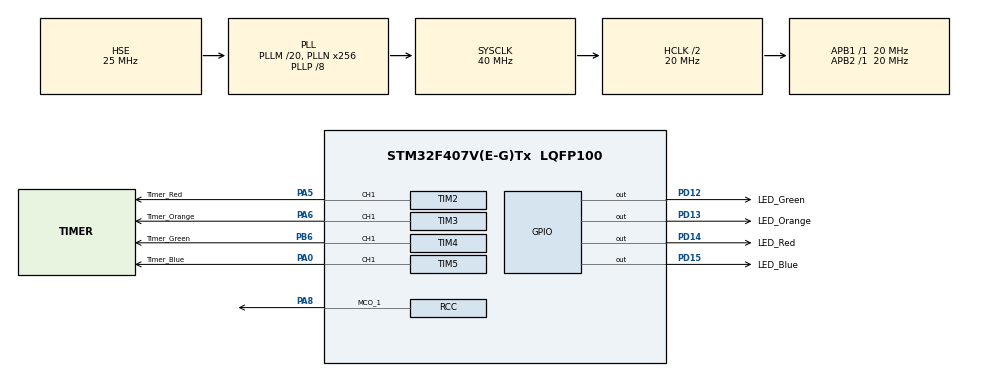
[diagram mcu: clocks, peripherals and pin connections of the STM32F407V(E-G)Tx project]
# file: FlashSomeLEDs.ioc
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Mcu.Family=STM32F4
Mcu.Name=STM32F407V(E-G)Tx
Mcu.Package=LQFP100
NVIC.PriorityGroup=NVIC_PRIORITYGROUP_4
NVIC.TIM2_IRQn=true\:0\:0\:false\:false\:true\:true\:true
NVIC.TIM3_IRQn=true\:0\:0\:false\:false\:true\:true\:true
NVIC.TIM4_IRQn=true\:0\:0\:false\:false\:true\:true\:true
NVIC.TIM5_IRQn=true\:0\:0\:false\:false\:true\:true\:true
PA0-WKUP.GPIO_Label=Timer_Blue
PA0-WKUP.Signal=S_TIM5_CH1
PA5.GPIO_Label=Timer_Red
PA5.Signal=S_TIM2_CH1_ETR
PA6.GPIO_Label=Timer_Orange
PA6.Signal=S_TIM3_CH1
PA8.Mode=Clock-out-1
PA8.Signal=RCC_MCO_1
PB6.GPIO_Label=Timer_Green
PB6.Signal=S_TIM4_CH1
PD12.GPIO_Label=LED_Green
PD12.Signal=GPIO_Output
PD13.GPIO_Label=LED_Orange
PD13.Signal=GPIO_Output
PD14.GPIO_Label=LED_Red
PD14.Signal=GPIO_Output
PD15.GPIO_Label=LED_Blue
PD15.Signal=GPIO_Output
PH0-OSC_IN.Mode=HSE-External-Oscillator
PH0-OSC_IN.Signal=RCC_OSC_IN
PH1-OSC_OUT.Mode=HSE-External-Oscillator
PH1-OSC_OUT.Signal=RCC_OSC_OUT
ProjectManager.HeapSize=0x200
ProjectManager.StackSize=0x400
ProjectManager.TargetToolchain=SW4STM32
RCC.48MHZClocksFreq_Value=80000000
RCC.AHBCLKDivider=RCC_SYSCLK_DIV2
RCC.AHBFreq_Value=20000000
RCC.APB1Freq_Value=20000000
RCC.APB1TimFreq_Value=20000000
RCC.APB2Freq_Value=20000000
RCC.APB2TimFreq_Value=20000000
RCC.CortexFreq_Value=20000000
RCC.HCLKFreq_Value=20000000
RCC.HSE_VALUE=25000000
RCC.HSI_VALUE=16000000
RCC.LSE_VALUE=32768
RCC.PLLM=20
RCC.PLLN=256
RCC.PLLP=RCC_PLLP_DIV8
RCC.PLLSourceVirtual=RCC_PLLSOURCE_HSE
RCC.SYSCLKFreq_VALUE=40000000
RCC.SYSCLKSource=RCC_SYSCLKSOURCE_PLLCLK
RCC.VCOOutputFreq_Value=320000000
SH.S_TIM2_CH1_ETR.0=TIM2_CH1,Output Compare1 CH1
SH.S_TIM3_CH1.0=TIM3_CH1,Output Compare1 CH1
SH.S_TIM4_CH1.0=TIM4_CH1,Output Compare1 CH1
SH.S_TIM5_CH1.0=TIM5_CH1,Output Compare1 CH1
TIM2.Channel-Output\ Compare1\ CH1=TIM_CHANNEL_1
TIM2.Period=2000
TIM2.Prescaler=1000
TIM3.Channel-Output\ Compare1\ CH1=TIM_CHANNEL_1
TIM3.Period=1000
TIM3.Prescaler=1000
TIM4.Channel-Output\ Compare1\ CH1=TIM_CHANNEL_1
TIM4.Period=4000
TIM4.Prescaler=1000
TIM5.Channel-Output\ Compare1\ CH1=TIM_CHANNEL_1
TIM5.Period=10000
TIM5.Prescaler=1000
board=custom

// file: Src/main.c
/* USER CODE BEGIN Header */
/**
  ******************************************************************************
  * @file           : main.c
  * @brief          : Main program body
  ******************************************************************************
  * @attention
  *
  * <h2><center>&copy; Copyright (c) 2019 STMicroelectronics.
  * All rights reserved.</center></h2>
  *
  * This software component is licensed by ST under BSD 3-Clause license,
  * the "License"; You may not use this file except in compliance with the
  * License. You may obtain a copy of the License at:
  *                        opensource.org/licenses/BSD-3-Clause
  *
  ******************************************************************************
  */
/* USER CODE END Header */

#include "main.h"

TIM_HandleTypeDef htim2;
TIM_HandleTypeDef htim3;
TIM_HandleTypeDef htim4;
TIM_HandleTypeDef htim5;

void SystemClock_Config(void);
static void MX_GPIO_Init(void);
static void MX_TIM2_Init(void);
static void MX_TIM3_Init(void);
static void MX_TIM4_Init(void);
static void MX_TIM5_Init(void);

int main(void)
{

  /* MCU Configuration--------------------------------------------------------*/

  /* Reset of all peripherals, Initializes the Flash interface and the Systick. */
  HAL_Init();

  /* Configure the system clock */
  SystemClock_Config();

  /* Initialize all configured peripherals */
  MX_GPIO_Init();
  MX_TIM2_Init();
  MX_TIM3_Init();
  MX_TIM4_Init();
  MX_TIM5_Init();
  /* USER CODE BEGIN 2 */
  InitRedTimerHandle(&htim2);
  InitOrangeTimerHandle(&htim3);
  InitBlueTimerHandle(&htim4);
  InitGreenTimerHandle(&htim5);
  /* USER CODE END 2 */

  /* Infinite loop */
  /* USER CODE BEGIN WHILE */
  while (1)
  {
	  FlashyLightsMain();
    /* USER CODE END WHILE */

  }
}

void SystemClock_Config(void)
{
  RCC_OscInitTypeDef RCC_OscInitStruct = {0};
  RCC_ClkInitTypeDef RCC_ClkInitStruct = {0};

  /** Configure the main internal regulator output voltage
  */
  __HAL_RCC_PWR_CLK_ENABLE();
  __HAL_PWR_VOLTAGESCALING_CONFIG(PWR_REGULATOR_VOLTAGE_SCALE1);
  /** Initializes the CPU, AHB and APB busses clocks
  */
  RCC_OscInitStruct.OscillatorType = RCC_OSCILLATORTYPE_HSI|RCC_OSCILLATORTYPE_HSE;
  RCC_OscInitStruct.HSEState = RCC_HSE_ON;
  RCC_OscInitStruct.HSIState = RCC_HSI_ON;
  RCC_OscInitStruct.HSICalibrationValue = RCC_HSICALIBRATION_DEFAULT;
  RCC_OscInitStruct.PLL.PLLState = RCC_PLL_ON;
  RCC_OscInitStruct.PLL.PLLSource = RCC_PLLSOURCE_HSE;
  RCC_OscInitStruct.PLL.PLLM = 20;
  RCC_OscInitStruct.PLL.PLLN = 256;
  RCC_OscInitStruct.PLL.PLLP = RCC_PLLP_DIV8;
  RCC_OscInitStruct.PLL.PLLQ = 4;
  if (HAL_RCC_OscConfig(&RCC_OscInitStruct) != HAL_OK)
  {
    Error_Handler();
  }
  /** Initializes the CPU, AHB and APB busses clocks
  */
  RCC_ClkInitStruct.ClockType = RCC_CLOCKTYPE_HCLK|RCC_CLOCKTYPE_SYSCLK
                              |RCC_CLOCKTYPE_PCLK1|RCC_CLOCKTYPE_PCLK2;
  RCC_ClkInitStruct.SYSCLKSource = RCC_SYSCLKSOURCE_PLLCLK;
  RCC_ClkInitStruct.AHBCLKDivider = RCC_SYSCLK_DIV2;
  RCC_ClkInitStruct.APB1CLKDivider = RCC_HCLK_DIV1;
  RCC_ClkInitStruct.APB2CLKDivider = RCC_HCLK_DIV1;

  if (HAL_RCC_ClockConfig(&RCC_ClkInitStruct, FLASH_LATENCY_0) != HAL_OK)
  {
    Error_Handler();
  }
  HAL_RCC_MCOConfig(RCC_MCO1, RCC_MCO1SOURCE_HSI, RCC_MCODIV_1);
}

static void MX_TIM2_Init(void)
{

  TIM_MasterConfigTypeDef sMasterConfig = {0};
  TIM_OC_InitTypeDef sConfigOC = {0};

  htim2.Instance = TIM2;
  htim2.Init.Prescaler = 1000;
  htim2.Init.CounterMode = TIM_COUNTERMODE_UP;
  htim2.Init.Period = 2000;
  htim2.Init.ClockDivision = TIM_CLOCKDIVISION_DIV1;
  htim2.Init.AutoReloadPreload = TIM_AUTORELOAD_PRELOAD_DISABLE;
  if (HAL_TIM_OC_Init(&htim2) != HAL_OK)
  {
    Error_Handler();
  }
  sMasterConfig.MasterOutputTrigger = TIM_TRGO_RESET;
  sMasterConfig.MasterSlaveMode = TIM_MASTERSLAVEMODE_DISABLE;
  if (HAL_TIMEx_MasterConfigSynchronization(&htim2, &sMasterConfig) != HAL_OK)
  {
    Error_Handler();
  }
  sConfigOC.OCMode = TIM_OCMODE_TIMING;
  sConfigOC.Pulse = 0;
  sConfigOC.OCPolarity = TIM_OCPOLARITY_HIGH;
  sConfigOC.OCFastMode = TIM_OCFAST_DISABLE;
  if (HAL_TIM_OC_ConfigChannel(&htim2, &sConfigOC, TIM_CHANNEL_1) != HAL_OK)
  {
    Error_Handler();
  }
  HAL_TIM_MspPostInit(&htim2);

}

static void MX_TIM3_Init(void)
{

  TIM_MasterConfigTypeDef sMasterConfig = {0};
  TIM_OC_InitTypeDef sConfigOC = {0};

  htim3.Instance = TIM3;
  htim3.Init.Prescaler = 1000;
  htim3.Init.CounterMode = TIM_COUNTERMODE_UP;
  htim3.Init.Period = 1000;
  htim3.Init.ClockDivision = TIM_CLOCKDIVISION_DIV1;
  htim3.Init.AutoReloadPreload = TIM_AUTORELOAD_PRELOAD_DISABLE;
  if (HAL_TIM_OC_Init(&htim3) != HAL_OK)
  {
    Error_Handler();
  }
  sMasterConfig.MasterOutputTrigger = TIM_TRGO_RESET;
  sMasterConfig.MasterSlaveMode = TIM_MASTERSLAVEMODE_DISABLE;
  if (HAL_TIMEx_MasterConfigSynchronization(&htim3, &sMasterConfig) != HAL_OK)
  {
    Error_Handler();
  }
  sConfigOC.OCMode = TIM_OCMODE_TIMING;
  sConfigOC.Pulse = 0;
  sConfigOC.OCPolarity = TIM_OCPOLARITY_HIGH;
  sConfigOC.OCFastMode = TIM_OCFAST_DISABLE;
  if (HAL_TIM_OC_ConfigChannel(&htim3, &sConfigOC, TIM_CHANNEL_1) != HAL_OK)
  {
    Error_Handler();
  }
  HAL_TIM_MspPostInit(&htim3);

}

static void MX_TIM4_Init(void)
{

  TIM_MasterConfigTypeDef sMasterConfig = {0};
  TIM_OC_InitTypeDef sConfigOC = {0};

  htim4.Instance = TIM4;
  htim4.Init.Prescaler = 1000;
  htim4.Init.CounterMode = TIM_COUNTERMODE_UP;
  htim4.Init.Period = 4000;
  htim4.Init.ClockDivision = TIM_CLOCKDIVISION_DIV1;
  htim4.Init.AutoReloadPreload = TIM_AUTORELOAD_PRELOAD_DISABLE;
  if (HAL_TIM_OC_Init(&htim4) != HAL_OK)
  {
    Error_Handler();
  }
  sMasterConfig.MasterOutputTrigger = TIM_TRGO_RESET;
  sMasterConfig.MasterSlaveMode = TIM_MASTERSLAVEMODE_DISABLE;
  if (HAL_TIMEx_MasterConfigSynchronization(&htim4, &sMasterConfig) != HAL_OK)
  {
    Error_Handler();
  }
  sConfigOC.OCMode = TIM_OCMODE_TIMING;
  sConfigOC.Pulse = 0;
  sConfigOC.OCPolarity = TIM_OCPOLARITY_HIGH;
  sConfigOC.OCFastMode = TIM_OCFAST_DISABLE;
  if (HAL_TIM_OC_ConfigChannel(&htim4, &sConfigOC, TIM_CHANNEL_1) != HAL_OK)
  {
    Error_Handler();
  }
  HAL_TIM_MspPostInit(&htim4);

}

static void MX_TIM5_Init(void)
{

  TIM_MasterConfigTypeDef sMasterConfig = {0};
  TIM_OC_InitTypeDef sConfigOC = {0};

  htim5.Instance = TIM5;
  htim5.Init.Prescaler = 1000;
  htim5.Init.CounterMode = TIM_COUNTERMODE_UP;
  htim5.Init.Period = 10000;
  htim5.Init.ClockDivision = TIM_CLOCKDIVISION_DIV1;
  htim5.Init.AutoReloadPreload = TIM_AUTORELOAD_PRELOAD_DISABLE;
  if (HAL_TIM_OC_Init(&htim5) != HAL_OK)
  {
    Error_Handler();
  }
  sMasterConfig.MasterOutputTrigger = TIM_TRGO_RESET;
  sMasterConfig.MasterSlaveMode = TIM_MASTERSLAVEMODE_DISABLE;
  if (HAL_TIMEx_MasterConfigSynchronization(&htim5, &sMasterConfig) != HAL_OK)
  {
    Error_Handler();
  }
  sConfigOC.OCMode = TIM_OCMODE_TIMING;
  sConfigOC.Pulse = 0;
  sConfigOC.OCPolarity = TIM_OCPOLARITY_HIGH;
  sConfigOC.OCFastMode = TIM_OCFAST_DISABLE;
  if (HAL_TIM_OC_ConfigChannel(&htim5, &sConfigOC, TIM_CHANNEL_1) != HAL_OK)
  {
    Error_Handler();
  }
  HAL_TIM_MspPostInit(&htim5);

}

static void MX_GPIO_Init(void)
{
  GPIO_InitTypeDef GPIO_InitStruct = {0};

  /* GPIO Ports Clock Enable */
  __HAL_RCC_GPIOH_CLK_ENABLE();
  __HAL_RCC_GPIOA_CLK_ENABLE();
  __HAL_RCC_GPIOD_CLK_ENABLE();
  __HAL_RCC_GPIOB_CLK_ENABLE();

  /*Configure GPIO pin Output Level */
  HAL_GPIO_WritePin(GPIOD, LED_Green_Pin|LED_Orange_Pin|LED_Red_Pin|LED_Blue_Pin, GPIO_PIN_RESET);

  /*Configure GPIO pins : LED_Green_Pin LED_Orange_Pin LED_Red_Pin LED_Blue_Pin */
  GPIO_InitStruct.Pin = LED_Green_Pin|LED_Orange_Pin|LED_Red_Pin|LED_Blue_Pin;
  GPIO_InitStruct.Mode = GPIO_MODE_OUTPUT_PP;
  GPIO_InitStruct.Pull = GPIO_NOPULL;
  GPIO_InitStruct.Speed = GPIO_SPEED_FREQ_LOW;
  HAL_GPIO_Init(GPIOD, &GPIO_InitStruct);

  /*Configure GPIO pin : PA8 */
  GPIO_InitStruct.Pin = GPIO_PIN_8;
  GPIO_InitStruct.Mode = GPIO_MODE_AF_PP;
  GPIO_InitStruct.Pull = GPIO_NOPULL;
  GPIO_InitStruct.Speed = GPIO_SPEED_FREQ_LOW;
  GPIO_InitStruct.Alternate = GPIO_AF0_MCO;
  HAL_GPIO_Init(GPIOA, &GPIO_InitStruct);

}

void Error_Handler(void)
{
}

/************************ (C) COPYRIGHT STMicroelectronics *****END OF FILE****/
